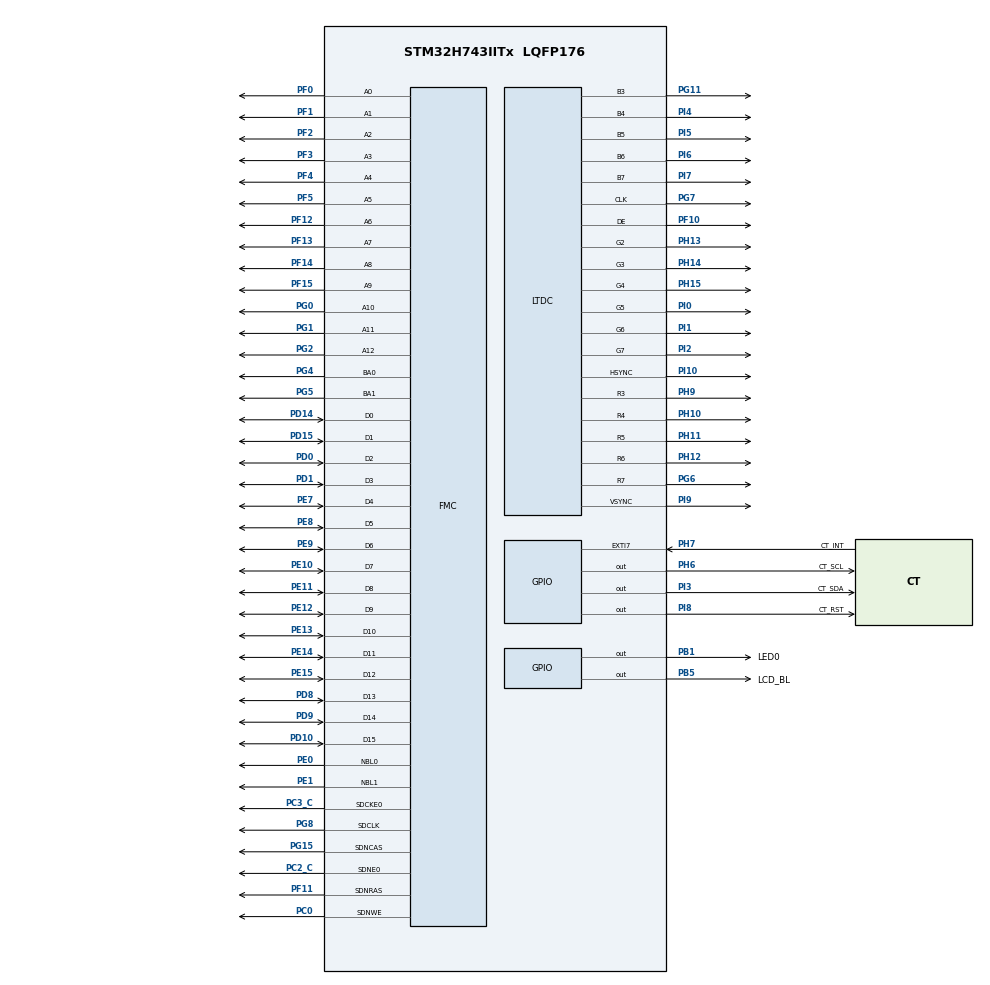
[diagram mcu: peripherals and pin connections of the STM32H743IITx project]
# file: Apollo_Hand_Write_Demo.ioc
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CORTEX_M7.AccessPermission_Spec=MPU_REGION_FULL_ACCESS
CORTEX_M7.MPU_Control=__NULL
CORTEX_M7.default_mode_Activation=1
DMA2D.ColorMode=DMA2D_OUTPUT_RGB565
FMC.CASLatency1=FMC_SDRAM_CAS_LATENCY_3
FMC.ColumnBitsNumber1=FMC_SDRAM_COLUMN_BITS_NUM_9
FMC.ExitSelfRefreshDelay1=10
FMC.LoadToActiveDelay1=2
FMC.RCDDelay1=2
FMC.RPDelay1=2
FMC.ReadBurst1=FMC_SDRAM_RBURST_ENABLE
FMC.ReadPipeDelay1=FMC_SDRAM_RPIPE_DELAY_1
FMC.RowCycleDelay1=8
FMC.SDClockPeriod1=FMC_SDRAM_CLOCK_PERIOD_2
FMC.SelfRefreshTime1=6
FMC.WriteRecoveryTime1=4
FREERTOS.BinarySemaphores01=semGetPoint,Dynamic,NULL
FREERTOS.Events01=eventGroup,Dynamic,NULL
FREERTOS.Tasks01=eventProcess,32,1024,eventProcessTask,As weak,NULL,Dynamic,NULL,NULL;TouchGFX,24,2048,TouchGFX_Task,As weak,NULL,Dynamic,NULL,NULL;drawLine,16,1024,drawLineTask,As weak,NULL,Dynamic,NULL,NULL
FREERTOS.configTOTAL_HEAP_SIZE=32768
LTDC.ActiveH=600
LTDC.ActiveW=1024
LTDC.Alpha_L0=255
LTDC.Alpha_L1=255
LTDC.BlendingFactor1_L1=LTDC_BLENDING_FACTOR1_PAxCA
LTDC.BlendingFactor2_L1=LTDC_BLENDING_FACTOR2_PAxCA
LTDC.FBStartAdress_L0=LTDC_L0_ADDR
LTDC.FBStartAdress_L1=LTDC_L1_ADDR
LTDC.HBP=140
LTDC.HFP=160
LTDC.HSync=20
LTDC.ImageHeight_L0=LTDC_L0_HEIGHT
LTDC.ImageHeight_L1=LTDC_L1_HEIGHT
LTDC.ImageWidth_L0=LTDC_L0_WIDTH
LTDC.ImageWidth_L1=LTDC_L1_WIDTH
LTDC.Layers=1
LTDC.PixelFormat_L0=LTDC_PIXEL_FORMAT_RGB565
LTDC.PixelFormat_L1=LTDC_PIXEL_FORMAT_RGB565
LTDC.VBP=20
LTDC.VFP=12
LTDC.VSync=3
LTDC.WindowX0_L1=LTDC_L1_START_X
LTDC.WindowX1_L0=LTDC_L0_WIDTH
LTDC.WindowX1_L1=(LTDC_L1_START_X + LTDC_L1_WIDTH)
LTDC.WindowY0_L1=LTDC_L1_START_Y
LTDC.WindowY1_L0=LTDC_L0_HEIGHT
LTDC.WindowY1_L1=(LTDC_L1_START_Y + LTDC_L1_HEIGHT)
Mcu.Family=STM32H7
Mcu.Name=STM32H743IITx
Mcu.Package=LQFP176
Mcu.UserConstants=LTDC_L1_ADDR,(LTDC_L0_ADDR + LTDC_FRAME_BUF_SIZE * 2);LTDC_FRAME_BUF_SIZE,(1024 * 600 * 2);LTDC_L0_ADDR,0xC0000000;LTDC_L0_WIDTH,1024;LTDC_L0_HEIGHT,600;LTDC_L1_WIDTH,300;LTDC_L1_HEIGHT,300;LTDC_L1_START_X,200;LTDC_L1_START_Y,180
NVIC.DMA2D_IRQn=true\:11\:0\:true\:false\:true\:true\:true\:true\:true
NVIC.LTDC_IRQn=true\:13\:0\:true\:false\:true\:true\:true\:true\:true
NVIC.PriorityGroup=NVIC_PRIORITYGROUP_4
NVIC.TIM7_IRQn=true\:15\:0\:false\:false\:true\:false\:false\:true\:true
NVIC.TimeBase=TIM7_IRQn
NVIC.TimeBaseIP=TIM7
PA13\ (JTMS/SWDIO).Mode=Serial_Wire
PA13\ (JTMS/SWDIO).Signal=DEBUG_JTMS-SWDIO
PA14\ (JTCK/SWCLK).Mode=Serial_Wire
PA14\ (JTCK/SWCLK).Signal=DEBUG_JTCK-SWCLK
PB1.GPIO_Label=LED0
PB1.GPIO_PuPd=GPIO_PULLUP
PB1.PinState=GPIO_PIN_SET
PB1.Signal=GPIO_Output
PB5.GPIO_Label=LCD_BL
PB5.GPIO_PuPd=GPIO_PULLDOWN
PB5.PinState=GPIO_PIN_RESET
PB5.Signal=GPIO_Output
PC0.Signal=FMC_SDNWE
PC2_C.Mode=SdramChipSelect1_1
PC2_C.Signal=FMC_SDNE0
PC3_C.Mode=SdramChipSelect1_1
PC3_C.Signal=FMC_SDCKE0
PD0.Signal=FMC_D2_DA2
PD1.Signal=FMC_D3_DA3
PD10.Signal=FMC_D15_DA15
PD14.Signal=FMC_D0_DA0
PD15.Signal=FMC_D1_DA1
PD6.GPIO_PuPd=GPIO_PULLUP
PD6.Signal=FMC_NWAIT
PD8.Signal=FMC_D13_DA13
PD9.Signal=FMC_D14_DA14
PE0.Signal=FMC_NBL0
PE1.Signal=FMC_NBL1
PE10.Signal=FMC_D7_DA7
PE11.Signal=FMC_D8_DA8
PE12.Signal=FMC_D9_DA9
PE13.Signal=FMC_D10_DA10
PE14.Signal=FMC_D11_DA11
PE15.Signal=FMC_D12_DA12
PE7.Signal=FMC_D4_DA4
PE8.Signal=FMC_D5_DA5
PE9.Signal=FMC_D6_DA6
PF0.Signal=FMC_A0
PF1.Signal=FMC_A1
PF10.GPIO_Speed=GPIO_SPEED_FREQ_VERY_HIGH
PF10.Mode=RGB565
PF10.Signal=LTDC_DE
PF11.Signal=FMC_SDNRAS
PF12.Signal=FMC_A6
PF13.Signal=FMC_A7
PF14.Signal=FMC_A8
PF15.Signal=FMC_A9
PF2.Signal=FMC_A2
PF3.Signal=FMC_A3
PF4.Signal=FMC_A4
PF5.Signal=FMC_A5
PG0.Signal=FMC_A10
PG1.Signal=FMC_A11
PG11.GPIO_Speed=GPIO_SPEED_FREQ_VERY_HIGH
PG11.Mode=RGB565
PG11.Signal=LTDC_B3
PG15.Signal=FMC_SDNCAS
PG2.Signal=FMC_A12
PG4.Signal=FMC_A14_BA0
PG5.Signal=FMC_A15_BA1
PG6.GPIO_Speed=GPIO_SPEED_FREQ_VERY_HIGH
PG6.Mode=RGB565
PG6.Signal=LTDC_R7
PG7.GPIO_Speed=GPIO_SPEED_FREQ_VERY_HIGH
PG7.Mode=RGB565
PG7.Signal=LTDC_CLK
PG8.Signal=FMC_SDCLK
PG9.Signal=FMC_NCE
PH0-OSC_IN\ (PH0).Mode=HSE-External-Oscillator
PH0-OSC_IN\ (PH0).Signal=RCC_OSC_IN
PH1-OSC_OUT\ (PH1).Mode=HSE-External-Oscillator
PH1-OSC_OUT\ (PH1).Signal=RCC_OSC_OUT
PH10.GPIO_Speed=GPIO_SPEED_FREQ_VERY_HIGH
PH10.Mode=RGB565
PH10.Signal=LTDC_R4
PH11.GPIO_Speed=GPIO_SPEED_FREQ_VERY_HIGH
PH11.Mode=RGB565
PH11.Signal=LTDC_R5
PH12.GPIO_Speed=GPIO_SPEED_FREQ_VERY_HIGH
PH12.Mode=RGB565
PH12.Signal=LTDC_R6
PH13.GPIO_Speed=GPIO_SPEED_FREQ_VERY_HIGH
PH13.Mode=RGB565
PH13.Signal=LTDC_G2
PH14.GPIO_Speed=GPIO_SPEED_FREQ_VERY_HIGH
PH14.Mode=RGB565
PH14.Signal=LTDC_G3
PH15.GPIO_Speed=GPIO_SPEED_FREQ_VERY_HIGH
PH15.Mode=RGB565
PH15.Signal=LTDC_G4
PH6.GPIO_Label=CT_SCL
PH6.GPIO_PuPd=GPIO_PULLUP
PH6.GPIO_Speed=GPIO_SPEED_FREQ_HIGH
PH6.PinState=GPIO_PIN_SET
PH6.Signal=GPIO_Output
PH7.GPIO_Label=CT_INT
PH7.GPIO_ModeDefaultEXTI=GPIO_MODE_IT_RISING
PH7.GPIO_PuPd=GPIO_PULLDOWN
PH7.Signal=GPXTI7
PH9.GPIO_Speed=GPIO_SPEED_FREQ_VERY_HIGH
PH9.Mode=RGB565
PH9.Signal=LTDC_R3
PI0.GPIO_Speed=GPIO_SPEED_FREQ_VERY_HIGH
PI0.Mode=RGB565
PI0.Signal=LTDC_G5
PI1.GPIO_Speed=GPIO_SPEED_FREQ_VERY_HIGH
PI1.Mode=RGB565
PI1.Signal=LTDC_G6
PI10.GPIO_Speed=GPIO_SPEED_FREQ_VERY_HIGH
PI10.Mode=RGB565
PI10.Signal=LTDC_HSYNC
PI2.GPIO_Speed=GPIO_SPEED_FREQ_VERY_HIGH
PI2.Mode=RGB565
PI2.Signal=LTDC_G7
PI3.GPIO_Label=CT_SDA
PI3.GPIO_PuPd=GPIO_PULLUP
PI3.GPIO_Speed=GPIO_SPEED_FREQ_HIGH
PI3.PinState=GPIO_PIN_SET
PI3.Signal=GPIO_Output
PI4.GPIO_Speed=GPIO_SPEED_FREQ_VERY_HIGH
PI4.Mode=RGB565
PI4.Signal=LTDC_B4
PI5.GPIO_Speed=GPIO_SPEED_FREQ_VERY_HIGH
PI5.Mode=RGB565
PI5.Signal=LTDC_B5
PI6.GPIO_Speed=GPIO_SPEED_FREQ_VERY_HIGH
PI6.Mode=RGB565
PI6.Signal=LTDC_B6
PI7.GPIO_Speed=GPIO_SPEED_FREQ_VERY_HIGH
PI7.Mode=RGB565
PI7.Signal=LTDC_B7
PI8.GPIO_Label=CT_RST
PI8.GPIO_PuPd=GPIO_PULLUP
PI8.PinState=GPIO_PIN_SET
PI8.Signal=GPIO_Output
PI9.GPIO_Speed=GPIO_SPEED_FREQ_VERY_HIGH
PI9.Mode=RGB565
PI9.Signal=LTDC_VSYNC
ProjectManager.HeapSize=0x200
ProjectManager.StackSize=0x1000
ProjectManager.TargetToolchain=MDK-ARM V5.32
RCC.ADCFreq_Value=260000000
RCC.APB1Freq_Value=120000000
RCC.APB2Freq_Value=120000000
RCC.APB3Freq_Value=120000000
RCC.APB4Freq_Value=120000000
RCC.CortexFreq_Value=480000000
RCC.D1PPRE=RCC_APB3_DIV2
RCC.D2PPRE1=RCC_APB1_DIV2
RCC.D2PPRE2=RCC_APB2_DIV2
RCC.D3PPRE=RCC_APB4_DIV2
RCC.DIVM1=5
RCC.DIVM2=5
RCC.DIVM3=5
RCC.DIVN1=192
RCC.DIVN2=104
RCC.DIVN3=40
RCC.DIVR3=4
RCC.FMCCLockSelection=RCC_FMCCLKSOURCE_PLL2
RCC.HCLKFreq_Value=240000000
RCC.HPRE=RCC_HCLK_DIV2
RCC.PLL2FRACN=0
RCC.PLL3FRACN=0
RCC.PLLFRACN=0
RCC.PLLSourceVirtual=RCC_PLLSOURCE_HSE
RCC.SYSCLKFreq_VALUE=480000000
RCC.SYSCLKSource=RCC_SYSCLKSOURCE_PLLCLK
RCC.USBFreq_Value=480000000
SH.FMC_A0.0=FMC_A0,13b-sda1
SH.FMC_A1.0=FMC_A1,13b-sda1
SH.FMC_A10.0=FMC_A10,13b-sda1
SH.FMC_A11.0=FMC_A11,13b-sda1
SH.FMC_A12.0=FMC_A12,13b-sda1
SH.FMC_A14_BA0.0=FMC_BA0,FourSdramBanks1
SH.FMC_A15_BA1.0=FMC_BA1,FourSdramBanks1
SH.FMC_A2.0=FMC_A2,13b-sda1
SH.FMC_A3.0=FMC_A3,13b-sda1
SH.FMC_A4.0=FMC_A4,13b-sda1
SH.FMC_A5.0=FMC_A5,13b-sda1
SH.FMC_A6.0=FMC_A6,13b-sda1
SH.FMC_A7.0=FMC_A7,13b-sda1
SH.FMC_A8.0=FMC_A8,13b-sda1
SH.FMC_A9.0=FMC_A9,13b-sda1
SH.FMC_D0_DA0.0=FMC_D0,sd-16b-d1
SH.FMC_D10_DA10.0=FMC_D10,sd-16b-d1
SH.FMC_D11_DA11.0=FMC_D11,sd-16b-d1
SH.FMC_D12_DA12.0=FMC_D12,sd-16b-d1
SH.FMC_D13_DA13.0=FMC_D13,sd-16b-d1
SH.FMC_D14_DA14.0=FMC_D14,sd-16b-d1
SH.FMC_D15_DA15.0=FMC_D15,sd-16b-d1
SH.FMC_D1_DA1.0=FMC_D1,sd-16b-d1
SH.FMC_D2_DA2.0=FMC_D2,sd-16b-d1
SH.FMC_D3_DA3.0=FMC_D3,sd-16b-d1
SH.FMC_D4_DA4.0=FMC_D4,sd-16b-d1
SH.FMC_D5_DA5.0=FMC_D5,sd-16b-d1
SH.FMC_D6_DA6.0=FMC_D6,sd-16b-d1
SH.FMC_D7_DA7.0=FMC_D7,sd-16b-d1
SH.FMC_D8_DA8.0=FMC_D8,sd-16b-d1
SH.FMC_D9_DA9.0=FMC_D9,sd-16b-d1
SH.FMC_NBL0.0=FMC_NBL0,Sd2ByteEnable1
SH.FMC_NBL1.0=FMC_NBL1,Sd2ByteEnable1
SH.FMC_NWAIT.0=FMC_NWAIT
SH.FMC_SDCLK.0=FMC_SDCLK,13b-sda1
SH.FMC_SDNCAS.0=FMC_SDNCAS,13b-sda1
SH.FMC_SDNRAS.0=FMC_SDNRAS,13b-sda1
SH.FMC_SDNWE.0=FMC_SDNWE,13b-sda1
STMicroelectronics.X-CUBE-TOUCHGFX.4.23.2.ApplicationCcGraphicsJjApplication=TouchGFXOoGenerator
STMicroelectronics.X-CUBE-TOUCHGFX.4.23.2.tgfx_address1=0xC0000000
STMicroelectronics.X-CUBE-TOUCHGFX.4.23.2.tgfx_address2=0xC012C000
STMicroelectronics.X-CUBE-TOUCHGFX.4.23.2.tgfx_buffering_strategy=Double
STMicroelectronics.X-CUBE-TOUCHGFX.4.23.2.tgfx_display_interface=disp_ltdc
STMicroelectronics.X-CUBE-TOUCHGFX.4.23.2.tgfx_hardware_accelerator=dma_2d
STMicroelectronics.X-CUBE-TOUCHGFX.4.23.2.tgfx_location=By Address
STMicroelectronics.X-CUBE-TOUCHGFX.4.23.2.tgfx_vsync=vsync_ltdc
STMicroelectronics.X-CUBE-TOUCHGFX.4.23.2_IsPackSelfContextualization=true
VP_CRC_VS_CRC.Mode=CRC_Activate
VP_DMA2D_VS_DMA2D.Mode=DMA2D_Activate
VP_FREERTOS_VS_CMSIS_V2.Mode=CMSIS_V2
VP_STMicroelectronics.X-CUBE-TOUCHGFX_VS_GraphicsJjApplication_4.23.2.Mode=GraphicsJjApplication
VP_SYS_VS_tim7.Mode=TIM7
board=custom

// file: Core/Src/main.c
/* USER CODE BEGIN Header */
/**
  ******************************************************************************
  * @file           : main.c
  * @brief          : Main program body
  ******************************************************************************
  * @attention
  *
  * Copyright (c) 2024 STMicroelectronics.
  * All rights reserved.
  *
  * This software is licensed under terms that can be found in the LICENSE file
  * in the root directory of this software component.
  * If no LICENSE file comes with this software, it is provided AS-IS.
  *
  ******************************************************************************
  */
/* USER CODE END Header */
#include "main.h"
#include "cmsis_os.h"
#include "crc.h"
#include "dma2d.h"
#include "ltdc.h"
#include "gpio.h"
#include "fmc.h"
#include "app_touchgfx.h"

/* USER CODE BEGIN Includes */
#include "dbger.h"
#include "gt911.h"
#include "sdram.h"
/* USER CODE END Includes */

void SystemClock_Config(void);
void MX_FREERTOS_Init(void);

int main(void)
{

  /* MCU Configuration--------------------------------------------------------*/

  /* Reset of all peripherals, Initializes the Flash interface and the Systick. */
  HAL_Init();

  /* Configure the system clock */
  SystemClock_Config();

  /* USER CODE BEGIN SysInit */
	LOG_INIT();
	LOG_DBG("\n\nApollo TouchGFX demo...\n");
  /* USER CODE END SysInit */

  /* Initialize all configured peripherals */
  MX_GPIO_Init();
  MX_FMC_Init();
  MX_DMA2D_Init();
  MX_LTDC_Init();
  MX_CRC_Init();
  MX_TouchGFX_Init();
  /* Call PreOsInit function */
  MX_TouchGFX_PreOSInit();
  /* USER CODE BEGIN 2 */
	// set the handwrite area to white
	memset((void*)LTDC_L1_ADDR, 0xFF, LTDC_L1_WIDTH * LTDC_L1_HEIGHT * 2);
	// enable LCD backlight
	HAL_GPIO_WritePin(LCD_BL_GPIO_Port, LCD_BL_Pin, GPIO_PIN_SET);
  /* USER CODE END 2 */

  /* Init scheduler */
  osKernelInitialize();

  /* Call init function for freertos objects (in cmsis_os2.c) */
  MX_FREERTOS_Init();

  /* Start scheduler */
  osKernelStart();

  /* We should never get here as control is now taken by the scheduler */

  /* Infinite loop */
  while (1)
  {

  }
}

void SystemClock_Config(void)
{
  RCC_OscInitTypeDef RCC_OscInitStruct = {0};
  RCC_ClkInitTypeDef RCC_ClkInitStruct = {0};

  /** Supply configuration update enable
  */
  HAL_PWREx_ConfigSupply(PWR_LDO_SUPPLY);

  /** Configure the main internal regulator output voltage
  */
  __HAL_PWR_VOLTAGESCALING_CONFIG(PWR_REGULATOR_VOLTAGE_SCALE1);

  while(!__HAL_PWR_GET_FLAG(PWR_FLAG_VOSRDY)) {}

  __HAL_RCC_SYSCFG_CLK_ENABLE();
  __HAL_PWR_VOLTAGESCALING_CONFIG(PWR_REGULATOR_VOLTAGE_SCALE0);

  while(!__HAL_PWR_GET_FLAG(PWR_FLAG_VOSRDY)) {}

  /** Initializes the RCC Oscillators according to the specified parameters
  * in the RCC_OscInitTypeDef structure.
  */
  RCC_OscInitStruct.OscillatorType = RCC_OSCILLATORTYPE_HSE;
  RCC_OscInitStruct.HSEState = RCC_HSE_ON;
  RCC_OscInitStruct.PLL.PLLState = RCC_PLL_ON;
  RCC_OscInitStruct.PLL.PLLSource = RCC_PLLSOURCE_HSE;
  RCC_OscInitStruct.PLL.PLLM = 5;
  RCC_OscInitStruct.PLL.PLLN = 192;
  RCC_OscInitStruct.PLL.PLLP = 2;
  RCC_OscInitStruct.PLL.PLLQ = 2;
  RCC_OscInitStruct.PLL.PLLR = 2;
  RCC_OscInitStruct.PLL.PLLRGE = RCC_PLL1VCIRANGE_2;
  RCC_OscInitStruct.PLL.PLLVCOSEL = RCC_PLL1VCOWIDE;
  RCC_OscInitStruct.PLL.PLLFRACN = 0;
  if (HAL_RCC_OscConfig(&RCC_OscInitStruct) != HAL_OK)
  {
    Error_Handler();
  }

  /** Initializes the CPU, AHB and APB buses clocks
  */
  RCC_ClkInitStruct.ClockType = RCC_CLOCKTYPE_HCLK|RCC_CLOCKTYPE_SYSCLK
                              |RCC_CLOCKTYPE_PCLK1|RCC_CLOCKTYPE_PCLK2
                              |RCC_CLOCKTYPE_D3PCLK1|RCC_CLOCKTYPE_D1PCLK1;
  RCC_ClkInitStruct.SYSCLKSource = RCC_SYSCLKSOURCE_PLLCLK;
  RCC_ClkInitStruct.SYSCLKDivider = RCC_SYSCLK_DIV1;
  RCC_ClkInitStruct.AHBCLKDivider = RCC_HCLK_DIV2;
  RCC_ClkInitStruct.APB3CLKDivider = RCC_APB3_DIV2;
  RCC_ClkInitStruct.APB1CLKDivider = RCC_APB1_DIV2;
  RCC_ClkInitStruct.APB2CLKDivider = RCC_APB2_DIV2;
  RCC_ClkInitStruct.APB4CLKDivider = RCC_APB4_DIV2;

  if (HAL_RCC_ClockConfig(&RCC_ClkInitStruct, FLASH_LATENCY_4) != HAL_OK)
  {
    Error_Handler();
  }
}

void HAL_TIM_PeriodElapsedCallback(TIM_HandleTypeDef *htim)
{
  if (htim->Instance == TIM7) {
    HAL_IncTick();
  }
}

void Error_Handler(void)
{
  __disable_irq();
  while (1)
  {
  }
}

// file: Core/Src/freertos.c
/* USER CODE BEGIN Header */
/**
  ******************************************************************************
  * File Name          : freertos.c
  * Description        : Code for freertos applications
  ******************************************************************************
  * @attention
  *
  * Copyright (c) 2024 STMicroelectronics.
  * All rights reserved.
  *
  * This software is licensed under terms that can be found in the LICENSE file
  * in the root directory of this software component.
  * If no LICENSE file comes with this software, it is provided AS-IS.
  *
  ******************************************************************************
  */
/* USER CODE END Header */

#include "FreeRTOS.h"
#include "task.h"
#include "main.h"
#include "cmsis_os.h"

/* USER CODE BEGIN Includes */
#include "gt911.h"
#include "dbger.h"
#include "atk_ncr.h"
/* USER CODE END Includes */

/* USER CODE BEGIN Variables */
volatile uint8_t recognize_finish = 0;
/* USER CODE END Variables */
/* Definitions for eventProcess */
osThreadId_t eventProcessHandle;
const osThreadAttr_t eventProcess_attributes = {
  .name = "eventProcess",
  .stack_size = 1024 * 4,
  .priority = (osPriority_t) osPriorityAboveNormal,
};
/* Definitions for TouchGFX */
osThreadId_t TouchGFXHandle;
const osThreadAttr_t TouchGFX_attributes = {
  .name = "TouchGFX",
  .stack_size = 2048 * 4,
  .priority = (osPriority_t) osPriorityNormal,
};
/* Definitions for drawLine */
osThreadId_t drawLineHandle;
const osThreadAttr_t drawLine_attributes = {
  .name = "drawLine",
  .stack_size = 1024 * 4,
  .priority = (osPriority_t) osPriorityBelowNormal,
};
/* Definitions for semGetPoint */
osSemaphoreId_t semGetPointHandle;
const osSemaphoreAttr_t semGetPoint_attributes = {
  .name = "semGetPoint"
};
/* Definitions for eventGroup */
osEventFlagsId_t eventGroupHandle;
const osEventFlagsAttr_t eventGroup_attributes = {
  .name = "eventGroup"
};

/* USER CODE BEGIN FunctionPrototypes */
void LTDC_draw_line(int16_t x1, int16_t y1, int16_t x2, int16_t y2, uint8_t width);
/* USER CODE END FunctionPrototypes */

void eventProcessTask(void *argument);
void TouchGFX_Task(void *argument);
void drawLineTask(void *argument);

void MX_FREERTOS_Init(void); /* (MISRA C 2004 rule 8.1) */

void MX_FREERTOS_Init(void) {

  /* Create the semaphores(s) */
  /* creation of semGetPoint */
  semGetPointHandle = osSemaphoreNew(1, 0, &semGetPoint_attributes);

  /* Create the thread(s) */
  /* creation of eventProcess */
  eventProcessHandle = osThreadNew(eventProcessTask, NULL, &eventProcess_attributes);

  /* creation of TouchGFX */
  TouchGFXHandle = osThreadNew(TouchGFX_Task, NULL, &TouchGFX_attributes);

  /* creation of drawLine */
  drawLineHandle = osThreadNew(drawLineTask, NULL, &drawLine_attributes);

  /* Create the event(s) */
  /* creation of eventGroup */
  eventGroupHandle = osEventFlagsNew(&eventGroup_attributes);

}

__weak void eventProcessTask(void *argument)
{
  /* USER CODE BEGIN eventProcessTask */

	// touch sensor init
	GT911_STA_t gt911_sta = GT911_STA_OK;
	gt911_sta = gt911_init();
	if(GT911_STA_OK != gt911_sta) {
		LOG_ERR("GT911 init err[%d]\n", gt911_sta);
	} else {
		LOG_DBG("GT911 init OK\n");
	}

	alientek_ncr_init();
  /* Infinite loop */
	uint32_t evt_id;
  for(;;)
  {
    evt_id = osEventFlagsWait(eventGroupHandle, EVT_ALL, osFlagsWaitAny, osWaitForever);
		if(evt_id & EVT_RECOGNIZE) {
			/* LOG_DBG("recognize...\n");
			for(uint16_t i = 0; i < point_num; i+=2) {
				LOG_DBG("P(%d,%d) P(%d,%d)\n", draw_coor[i].x, draw_coor[i].y, draw_coor[i+1].x, draw_coor[i+1].y);
				osDelay(2);
			} */
			alientek_ncr(draw_coor, point_num, CHAR_NUM/2, RECOGNIZE_123, result);
			alientek_ncr(draw_coor, point_num, CHAR_NUM/2, RECOGNIZE_ABC, &result[3]);
			recognize_finish = 1;
			LOG_DBG("point_num[%d] result: %s\n", point_num, result);
		}
  }
  /* USER CODE END eventProcessTask */
}

__weak void TouchGFX_Task(void *argument)
{
  /* USER CODE BEGIN TouchGFX_Task */
	char* color[] = {"red", "green", "blue"};
	uint16_t color_code[] = {0xF800, 0x07E0, 0x001F};
	uint8_t cur_color = 0;
  /* Infinite loop */
  for(;;)
  {
    osDelay(3000);
		HAL_GPIO_TogglePin(LED0_GPIO_Port, LED0_Pin);
		LOG_DBG("change color to %s\n", color[cur_color]);
		for(uint32_t i = 0; i < 1024*600*2; i += 2) {
			*(uint16_t*)(0xC0000000 + i) = color_code[cur_color];
			//*(uint16_t*)(0xC0000000 + i) = *(uint16_t*)(0xC1000000 + 1024*600*2 * cur_color + i);
		}
		if(++cur_color >= 3) {
			cur_color = 0;
		}
  }
  /* USER CODE END TouchGFX_Task */
}

__weak void drawLineTask(void *argument)
{
  /* USER CODE BEGIN drawLineTask */
	osDelay(100);	// waiting GT911 init
	osSemaphoreRelease(semGetPointHandle);
  /* Infinite loop */
  for(;;)
  {
    osSemaphoreAcquire(semGetPointHandle, osWaitForever);
		gt911_get_touch(touch_coordinate, &num_touched);
		if(num_touched == 0) {
			osDelay(5);
			osSemaphoreRelease(semGetPointHandle);
		} else {

			if(touch_coordinate[0].x > LTDC_L1_START_X && touch_coordinate[0].x < LTDC_L1_START_X + LTDC_L1_WIDTH &&
				 touch_coordinate[0].y > LTDC_L1_START_Y && touch_coordinate[0].y < LTDC_L1_START_Y + LTDC_L1_HEIGHT)
			{
				static COORDINATE_t last_point = {.x = 0, .y = 0};
				static uint32_t last_point_tick = 0;
				if(last_point.x == touch_coordinate[0].x && last_point.y == touch_coordinate[0].y) {
					last_point_tick = HAL_GetTick();
				} else {
					uint32_t now = HAL_GetTick();
					if(now - last_point_tick > 50) {
						last_point.x = touch_coordinate[0].x;
						last_point.y = touch_coordinate[0].y;
						if(point_num < MAX_POINT) {
							draw_coor[point_num].x = touch_coordinate[0].x;
							draw_coor[point_num++].y = touch_coordinate[0].y;
						} else {
							LOG_WAR("MAX_POINT[%d] is too small\n", MAX_POINT);
						}
					} else {
						// draw line
						#define LINE_WIDTH	2
						LOG_DBG("(%d, %d) --> (%d, %d)\n", last_point.x, last_point.y, touch_coordinate[0].x, touch_coordinate[0].y);
						if(last_point.x < LTDC_L1_START_X + LINE_WIDTH) {
							last_point.x = LTDC_L1_START_X + LINE_WIDTH;
						}
						if(last_point.x > LTDC_L1_START_X + LTDC_L1_WIDTH - LINE_WIDTH) {
							last_point.x = LTDC_L1_START_X + LTDC_L1_WIDTH - LINE_WIDTH;
						}
						if(last_point.y < LTDC_L1_START_Y + LINE_WIDTH) {
							last_point.y = LTDC_L1_START_Y + LINE_WIDTH;
						}
						if(last_point.y > LTDC_L1_START_Y + LTDC_L1_HEIGHT - LINE_WIDTH) {
							last_point.y = LTDC_L1_START_Y + LTDC_L1_HEIGHT - LINE_WIDTH;
						}
						if(touch_coordinate[0].x < LTDC_L1_START_X + LINE_WIDTH) {
							touch_coordinate[0].x = LTDC_L1_START_X + LINE_WIDTH;
						}
						if(touch_coordinate[0].x > LTDC_L1_START_X + LTDC_L1_WIDTH - LINE_WIDTH) {
							touch_coordinate[0].x = LTDC_L1_START_X + LTDC_L1_WIDTH - LINE_WIDTH;
						}
						if(touch_coordinate[0].y < LTDC_L1_START_Y + LINE_WIDTH) {
							touch_coordinate[0].y = LTDC_L1_START_Y + LINE_WIDTH;
						}
						if(touch_coordinate[0].y > LTDC_L1_START_Y + LTDC_L1_HEIGHT - LINE_WIDTH) {
							touch_coordinate[0].y = LTDC_L1_START_Y + LTDC_L1_HEIGHT - LINE_WIDTH;
						}
						LTDC_draw_line(last_point.x, last_point.y, touch_coordinate[0].x, touch_coordinate[0].y, LINE_WIDTH);
						last_point.x = touch_coordinate[0].x;
						last_point.y = touch_coordinate[0].y;
						if(point_num < MAX_POINT) {
							draw_coor[point_num].x = touch_coordinate[0].x;
							draw_coor[point_num++].y = touch_coordinate[0].y;
						} else {
							LOG_WAR("MAX_POINT[%d] is too small\n", MAX_POINT);
						}
					}
					last_point_tick = now;
				}
				osSemaphoreRelease(semGetPointHandle);
			}

		}
  }
  /* USER CODE END drawLineTask */
}
